# LF1000 register map
Vendor: MagicEyes Digital, Inc.; Series: POLLUX; File version: 1.2
ARM 32-bit ARM9 Application processor clocked up to 533 MHz
CPU: other r5p0, little endian, MPU, no FPU, I-cache, D-cache, ITCM, DTCM, 0 interrupt priority bits
Registers are 32-bit, read-write, reset 0x0 unless marked. A register's access mark holds for its fields unless they carry their own. Offsets are from the block's base; lines under a group give offsets from that group; [hi:lo] are bit positions; {n}, {i} and the like mark numbered series; 'fields as' and 'values as' point back to an identical list; <NAME> marks a mode.

## Memory map
0xC0000800 INTCON size 0x80 — Interrupt controller
0xC0001800 TIMER0 size 0x80 — 32-bit timer/up counter with auto-reload
0xC0001880 TIMER1 size 0x80
0xC0001900 TIMER2 size 0x80
0xC0001980 TIMER3 size 0x80
0xC0001A00 TIMER4 size 0x80

## Interrupts
4 TIMER0 — Timer 0 interrupt
11 TIMER1 — Timer 1 interrupt
15 TIMER2 — Timer 2 interrupt
21 TIMER2 (TIMER3) — Timer 3 interrupt
43 TIMER4 — Timer 4 interrupt

## TIMER0 — 32-bit timer/up counter with auto-reload
Base 0xC0001800
Same registers: TIMER1 0xC0001880, TIMER2 0xC0001900, TIMER3 0xC0001980, TIMER4 0xC0001A00
0x00 COUNT
0x04 MATCH
0x08 CONTROL
  [6] LDCNT write — Updates the COUNT register for reading
    0=Nop; 1=Load
  [5] INTPEND — Interrupt pending
    0=Not pending; 1=Pending
  [4] INTENB — Interrupt enable
    0=Disabled; 1=Enabled
  [2] WDENB — Watchdog enable
    0=Disabled; 1=Enabled
  [2] RUN — Timer stop/run
    0=Stop; 1=Run
  [1:0] SELTCLK — Timer clock select
    0=/2 (Timer clock / 2); 1=/4 (Timer clock / 4); 2=/8 (Timer clock / 8); 3=/1 (Timer clock / 1)
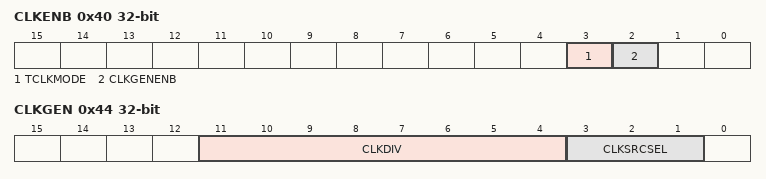
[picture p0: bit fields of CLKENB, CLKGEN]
0x40 CLKENB — Timer clock generation enable
  [3] TCLKMODE — Determines the TCLK operation mode
    0=Only on cpu access; 1=Always
  [2] CLKGENENB — Enables/disables clock generation
    0=Disable; 1=Enable
0x44 CLKGEN — Timer clock generation control
  [11:4] CLKDIV — Clock divider
  [3:1] CLKSRCSEL — Clock source selection
    0=PLL0; 1=PLL1

## Licence text in the file
Copyright (C) 2020 Jeff Kent <jeff@jkent.net> . Redistribution and use in source and binary forms, with or without modification, are permitted provided that the following conditions are met: . 1. Redistributions of source code must retain the above copyright notice, this list of conditions and the following disclaimer. . 2. Redistributions in binary form must reproduce the above copyright notice, this list of conditions and the following disclaimer in the documentation and/or other materials provided with the distribution. . 3. Neither the name of the copyright holder nor the names of its contributors may be used to endorse or promote products derived from this software without specific prior written permission. . THIS SOFTWARE IS PROVIDED BY THE COPYRIGHT HOLDERS AND CONTRIBUTORS "AS IS" AND ANY EXPRESS OR IMPLIED WARRANTIES, INCLUDING, BUT NOT LIMITED TO, THE. IMPLIED WARRANTIES OF MERCHANTABILITY AND FITNESS FOR A PARTICULAR PURPOSE. ARE DISCLAIMED. IN NO EVENT SHALL THE COPYRIGHT HOLDER OR CONTRIBUTORS BE. LIABLE FOR ANY DIRECT, INDIRECT, INCIDENTAL, SPECIAL, EXEMPLARY, OR. CONSEQUENTIAL DAMAGES (INCLUDING, BUT NOT LIMITED TO, PROCUREMENT OF. SUBSTITUTE GOODS OR SERVICES; LOSS OF USE, DATA, OR PROFITS; OR BUSINESS. INTERRUPTION) HOWEVER CAUSED AND ON ANY THEORY OF LIABILITY, WHETHER IN. CONTRACT, STRICT LIABILITY, OR TORT (INCLUDING NEGLIGENCE OR OTHERWISE). ARISING IN ANY WAY OUT OF THE USE OF THIS SOFTWARE, EVEN IF ADVISED OF THE. POSSIBILITY OF SUCH DAMAGE.
